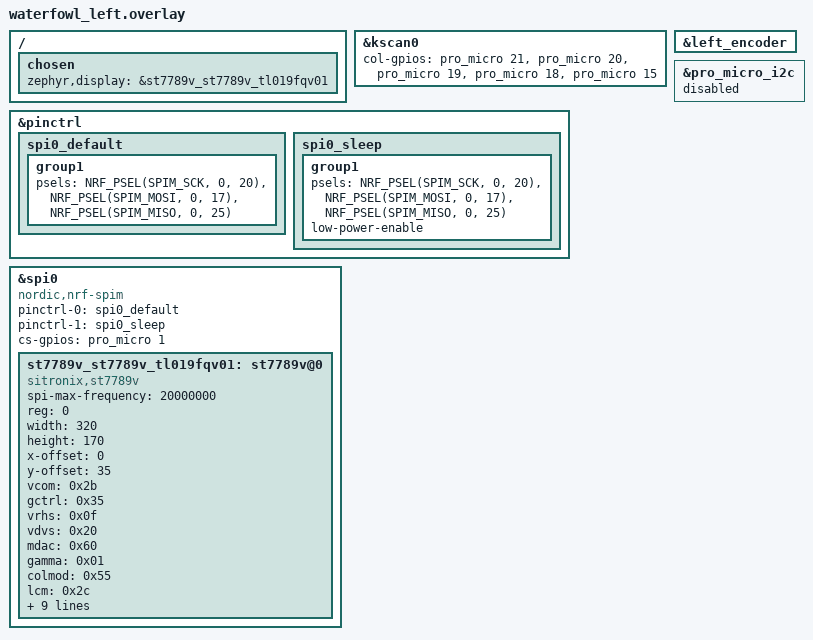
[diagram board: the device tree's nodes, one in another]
/*
 * Copyright (c) 2022 The ZMK Contributors
 *
 * SPDX-License-Identifier: MIT
 */

#include "waterfowl.dtsi"

/ {
	chosen {
		zephyr,display = &st7789v_st7789v_tl019fqv01;
	};
};

&kscan0 {
    col-gpios
        = <&pro_micro 21 GPIO_ACTIVE_HIGH>
        , <&pro_micro 20 GPIO_ACTIVE_HIGH>
        , <&pro_micro 19 GPIO_ACTIVE_HIGH>
        , <&pro_micro 18 GPIO_ACTIVE_HIGH>
        , <&pro_micro 15 GPIO_ACTIVE_HIGH>
        ;
};

&left_encoder {
    status = "okay";
};

&pinctrl {
    spi0_default: spi0_default {
        group1 {
            psels = <NRF_PSEL(SPIM_SCK, 0, 20)>,
                <NRF_PSEL(SPIM_MOSI, 0, 17)>,
                <NRF_PSEL(SPIM_MISO, 0, 25)>;
        };
    };
    spi0_sleep: spi0_sleep {
        group1 {
            psels = <NRF_PSEL(SPIM_SCK, 0, 20)>,
                <NRF_PSEL(SPIM_MOSI, 0, 17)>,
                <NRF_PSEL(SPIM_MISO, 0, 25)>;
            low-power-enable;
        };
    };
};

nice_view_spi: &spi0 {
    compatible = "nordic,nrf-spim";
    pinctrl-0 = <&spi0_default>;
    pinctrl-1 = <&spi0_sleep>;
    pinctrl-names = "default", "sleep";
    cs-gpios = <&pro_micro 1 GPIO_ACTIVE_HIGH>;

	st7789v_st7789v_tl019fqv01: st7789v@0 {
		compatible = "sitronix,st7789v";
		spi-max-frequency = <20000000>;
		reg = <0>;
		width = <320>;
		height = <170>;
		x-offset = <0>;
		y-offset = <35>;
		vcom = <0x2b>;
		gctrl = <0x35>;
		vrhs = <0x0f>;
		vdvs = <0x20>;
		mdac = <0x60>;
		gamma = <0x01>;
		colmod = <0x55>;
		lcm = <0x2c>;
		porch-param = [0c 0c 00 33 33];
		cmd2en-param = [5a 69 02 01];
		pwctrl1-param = [52 a1];
		pvgam-param = [D0 00 02 07 0B 1A 31 54 40 29 12 12 12 17];
		nvgam-param = [D0 00 02 07 05 15 2D 44 44 1C 18 16 1C 1D];
		ram-param = [00 F8];
		rgb-param = [CD 08 14];
	};
};

&pro_micro_i2c {
    status = "disabled";
};

